AUTOSAR XML (schema 4-2-2)
package /STELLANTIS/EPT/ASWCs
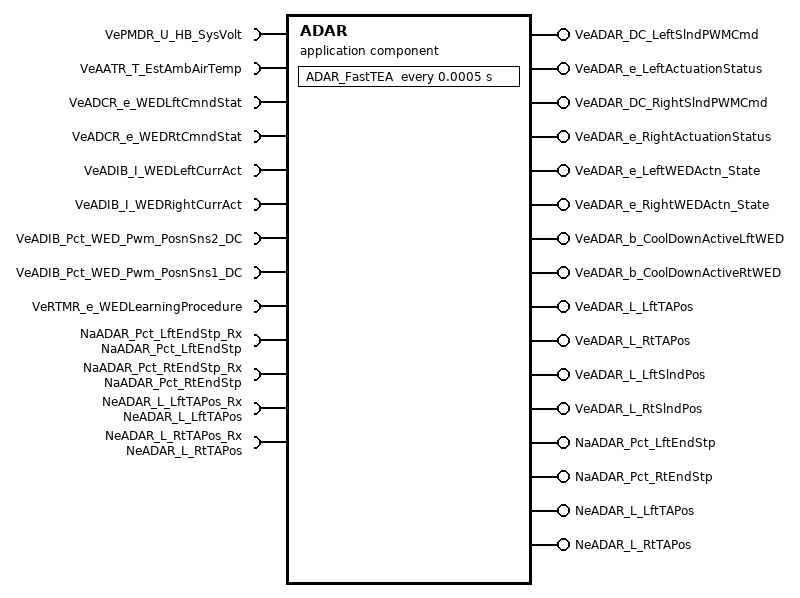
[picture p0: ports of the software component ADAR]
  application sw component type ADAR
    9 x require port:
      VePMDR_U_HB_SysVolt: variation-point={short-label=vpVePMDR_U_HB_SysVolt, sw-syscond=1}, nonqueued-receiver-com-spec{data-element=Value, init-value=0}, required-interface=VePMDR_U_HB_SysVolt
      VeAATR_T_EstAmbAirTemp: variation-point={short-label=vpVeAATR_T_EstAmbAirTemp, sw-syscond=1}, nonqueued-receiver-com-spec{data-element=Value, init-value=0}, required-interface=VeAATR_T_EstAmbAirTemp
      VeADCR_e_WEDLftCmndStat: variation-point={short-label=vpVeADCR_e_WEDLftCmndStat, sw-syscond=1}, nonqueued-receiver-com-spec{data-element=Value, init-value=CeADCR_e_NoCmnd}, required-interface=VeADCR_e_WEDLftCmndStat
      VeADCR_e_WEDRtCmndStat: variation-point={short-label=vpVeADCR_e_WEDRtCmndStat, sw-syscond=1}, nonqueued-receiver-com-spec{data-element=Value, init-value=CeADCR_e_NoCmnd}, required-interface=VeADCR_e_WEDRtCmndStat
      VeADIB_I_WEDLeftCurrAct: variation-point={short-label=vpVeADIB_I_WEDLeftCurrAct, sw-syscond=1}, nonqueued-receiver-com-spec{data-element=Value, init-value=0}, required-interface=VeADIB_I_WEDLeftCurrAct
      VeADIB_I_WEDRightCurrAct: variation-point={short-label=vpVeADIB_I_WEDRightCurrAct, sw-syscond=1}, nonqueued-receiver-com-spec{data-element=Value, init-value=0}, required-interface=VeADIB_I_WEDRightCurrAct
      VeADIB_Pct_WED_Pwm_PosnSns2_DC: variation-point={short-label=vpVeADIB_Pct_WED_Pwm_PosnSns2_DC, sw-syscond=1}, nonqueued-receiver-com-spec{data-element=Value, init-value=0}, required-interface=VeADIB_Pct_WED_Pwm_PosnSns2_DC
      VeADIB_Pct_WED_Pwm_PosnSns1_DC: variation-point={short-label=vpVeADIB_Pct_WED_Pwm_PosnSns1_DC, sw-syscond=1}, nonqueued-receiver-com-spec{data-element=Value, init-value=0}, required-interface=VeADIB_Pct_WED_Pwm_PosnSns1_DC
      VeRTMR_e_WEDLearningProcedure: variation-point={short-label=vpVeRTMR_e_WEDLearningProcedure, sw-syscond=1}, nonqueued-receiver-com-spec{data-element=Value, init-value=CeRTMR_e_WED_Not_Active}, required-interface=VeRTMR_e_WEDLearningProcedure
    12 x provide port:
      VeADAR_DC_LeftSlndPWMCmd: nonqueued-sender-com-spec{data-element=Value, init-value=0}, provided-interface=VeADAR_DC_LeftSlndPWMCmd
      VeADAR_e_LeftActuationStatus: nonqueued-sender-com-spec{data-element=Value, init-value=CeADAR_e_SS_Indeterminate}, provided-interface=VeADAR_e_LeftActuationStatus
      VeADAR_DC_RightSlndPWMCmd: nonqueued-sender-com-spec{data-element=Value, init-value=0}, provided-interface=VeADAR_DC_RightSlndPWMCmd
      VeADAR_e_RightActuationStatus: nonqueued-sender-com-spec{data-element=Value, init-value=CeADAR_e_SS_Indeterminate}, provided-interface=VeADAR_e_RightActuationStatus
      VeADAR_e_LeftWEDActn_State: nonqueued-sender-com-spec{data-element=Value, init-value=CeADAR_e_Indeterminate}, provided-interface=VeADAR_e_LeftWEDActn_State
      VeADAR_e_RightWEDActn_State: nonqueued-sender-com-spec{data-element=Value, init-value=CeADAR_e_Indeterminate}, provided-interface=VeADAR_e_RightWEDActn_State
      VeADAR_b_CoolDownActiveLftWED: nonqueued-sender-com-spec{data-element=Value, init-value=0}, provided-interface=VeADAR_b_CoolDownActiveLftWED
      VeADAR_b_CoolDownActiveRtWED: nonqueued-sender-com-spec{data-element=Value, init-value=0}, provided-interface=VeADAR_b_CoolDownActiveRtWED
      VeADAR_L_LftTAPos: nonqueued-sender-com-spec{data-element=Value, init-value=0}, provided-interface=VeADAR_L_LftTAPos
      VeADAR_L_RtTAPos: nonqueued-sender-com-spec{data-element=Value, init-value=0}, provided-interface=VeADAR_L_RtTAPos
      VeADAR_L_LftSlndPos: nonqueued-sender-com-spec{data-element=Value, init-value=0}, provided-interface=VeADAR_L_LftSlndPos
      VeADAR_L_RtSlndPos: nonqueued-sender-com-spec{data-element=Value, init-value=0}, provided-interface=VeADAR_L_RtSlndPos
    4 x require port:
      NaADAR_Pct_LftEndStp_Rx: nv-require-com-spec{init-value=[0, 0, 0, 0], variable=NaADAR_Pct_LftEndStp}, required-interface=NaADAR_Pct_LftEndStp
      NaADAR_Pct_RtEndStp_Rx: nv-require-com-spec{init-value=[0, 0, 0, 0], variable=NaADAR_Pct_RtEndStp}, required-interface=NaADAR_Pct_RtEndStp
      NeADAR_L_LftTAPos_Rx: nv-require-com-spec{init-value=0, variable=NeADAR_L_LftTAPos}, required-interface=NeADAR_L_LftTAPos
      NeADAR_L_RtTAPos_Rx: nv-require-com-spec{init-value=0, variable=NeADAR_L_RtTAPos}, required-interface=NeADAR_L_RtTAPos
    4 x provide port:
      NaADAR_Pct_LftEndStp: nv-provide-com-spec{ram-block-init-value=[0, 0, 0, 0], variable=NaADAR_Pct_LftEndStp}, provided-interface=NaADAR_Pct_LftEndStp
      NaADAR_Pct_RtEndStp: nv-provide-com-spec{ram-block-init-value=[0, 0, 0, 0], variable=NaADAR_Pct_RtEndStp}, provided-interface=NaADAR_Pct_RtEndStp
      NeADAR_L_LftTAPos: nv-provide-com-spec{ram-block-init-value=0, variable=NeADAR_L_LftTAPos}, provided-interface=NeADAR_L_LftTAPos
      NeADAR_L_RtTAPos: nv-provide-com-spec{ram-block-init-value=0, variable=NeADAR_L_RtTAPos}, provided-interface=NeADAR_L_RtTAPos
    behavior IB_ADAR: data-type-mapping=msADTtoIDTMapping, handle-termination-and-restart=NO-SUPPORT, included-data-type-set=data-type=[TeADAR_e_ActuationStages, TeADAR_e_CurrntProtectionStatus]
      timing event Event_FastTEA: start-on-event=ADAR_FastTEA, period=0.0005
      init event Event_ADAR_ac_Init: start-on-event=ADAR_ac_Init
      init event Event_PwrOn: start-on-event=ADAR_PwrOn
      init event Event_PwrOff: start-on-event=ADAR_PwrOff
      4 x runnable:
        ADAR_ac_Init
          data-send-points:
            4 x access:
              OUT_VeADAR_e_LeftActuationStatus_Value: accessed-variable=VeADAR_e_LeftActuationStatus.Value
              OUT_VeADAR_e_RightActuationStatus_Value: accessed-variable=VeADAR_e_RightActuationStatus.Value
              OUT_VeADAR_e_LeftWEDActn_State_Value: accessed-variable=VeADAR_e_LeftWEDActn_State.Value
              OUT_VeADAR_e_RightWEDActn_State_Value: accessed-variable=VeADAR_e_RightWEDActn_State.Value
        ADAR_PwrOn
          data-receive-point-by-arguments:
            4 x access:
              IN_NaADAR_Pct_LftEndStp_Rx_NaADAR_Pct_LftEndStp: accessed-variable=NaADAR_Pct_LftEndStp_Rx.NaADAR_Pct_LftEndStp
              IN_NaADAR_Pct_RtEndStp_Rx_NaADAR_Pct_RtEndStp: accessed-variable=NaADAR_Pct_RtEndStp_Rx.NaADAR_Pct_RtEndStp
              IN_NeADAR_L_LftTAPos_Rx_NeADAR_L_LftTAPos: accessed-variable=NeADAR_L_LftTAPos_Rx.NeADAR_L_LftTAPos
              IN_NeADAR_L_RtTAPos_Rx_NeADAR_L_RtTAPos: accessed-variable=NeADAR_L_RtTAPos_Rx.NeADAR_L_RtTAPos
          data-send-points:
            12 x access:
              OUT_VeADAR_e_LeftActuationStatus_Value: accessed-variable=VeADAR_e_LeftActuationStatus.Value
              OUT_VeADAR_DC_LeftSlndPWMCmd_Value: accessed-variable=VeADAR_DC_LeftSlndPWMCmd.Value
              OUT_VeADAR_e_RightActuationStatus_Value: accessed-variable=VeADAR_e_RightActuationStatus.Value
              OUT_VeADAR_DC_RightSlndPWMCmd_Value: accessed-variable=VeADAR_DC_RightSlndPWMCmd.Value
              OUT_VeADAR_e_LeftWEDActn_State_Value: accessed-variable=VeADAR_e_LeftWEDActn_State.Value
              OUT_VeADAR_e_RightWEDActn_State_Value: accessed-variable=VeADAR_e_RightWEDActn_State.Value
              OUT_VeADAR_b_CoolDownActiveLftWED_Value: accessed-variable=VeADAR_b_CoolDownActiveLftWED.Value
              OUT_VeADAR_b_CoolDownActiveRtWED_Value: accessed-variable=VeADAR_b_CoolDownActiveRtWED.Value
              OUT_VeADAR_L_LftTAPos_Value: accessed-variable=VeADAR_L_LftTAPos.Value
              OUT_VeADAR_L_RtTAPos_Value: accessed-variable=VeADAR_L_RtTAPos.Value
              OUT_VeADAR_L_LftSlndPos_Value: accessed-variable=VeADAR_L_LftSlndPos.Value
              OUT_VeADAR_L_RtSlndPos_Value: accessed-variable=VeADAR_L_RtSlndPos.Value
        ADAR_FastTEA
          data-receive-point-by-arguments:
            9 x access:
              IN_VeAATR_T_EstAmbAirTemp_Value: accessed-variable=VeAATR_T_EstAmbAirTemp.Value, variation-point={short-label=vpIN_VeAATR_T_EstAmbAirTemp_Value, sw-syscond=1}
              IN_VeADCR_e_WEDLftCmndStat_Value: accessed-variable=VeADCR_e_WEDLftCmndStat.Value, variation-point={short-label=vpIN_VeADCR_e_WEDLftCmndStat_Value, sw-syscond=1}
              IN_VeADCR_e_WEDRtCmndStat_Value: accessed-variable=VeADCR_e_WEDRtCmndStat.Value, variation-point={short-label=vpIN_VeADCR_e_WEDRtCmndStat_Value, sw-syscond=1}
              IN_VeADIB_I_WEDLeftCurrAct_Value: accessed-variable=VeADIB_I_WEDLeftCurrAct.Value, variation-point={short-label=vpIN_VeADIB_I_WEDLeftCurrAct_Value, sw-syscond=1}
              IN_VeADIB_I_WEDRightCurrAct_Value: accessed-variable=VeADIB_I_WEDRightCurrAct.Value, variation-point={short-label=vpIN_VeADIB_I_WEDRightCurrAct_Value, sw-syscond=1}
              IN_VeADIB_Pct_WED_Pwm_PosnSns1_DC_Value: accessed-variable=VeADIB_Pct_WED_Pwm_PosnSns1_DC.Value, variation-point={short-label=vpIN_VeADIB_Pct_WED_Pwm_PosnSns1_DC_Value, sw-syscond=1}
              IN_VeADIB_Pct_WED_Pwm_PosnSns2_DC_Value: accessed-variable=VeADIB_Pct_WED_Pwm_PosnSns2_DC.Value, variation-point={short-label=vpIN_VeADIB_Pct_WED_Pwm_PosnSns2_DC_Value, sw-syscond=1}
              IN_VePMDR_U_HB_SysVolt_Value: accessed-variable=VePMDR_U_HB_SysVolt.Value, variation-point={short-label=vpIN_VePMDR_U_HB_SysVolt_Value, sw-syscond=1}
              IN_VeRTMR_e_WEDLearningProcedure_Value: accessed-variable=VeRTMR_e_WEDLearningProcedure.Value, variation-point={short-label=vpIN_VeRTMR_e_WEDLearningProcedure_Value, sw-syscond=1}
          data-send-points:
            12 x access:
              OUT_VeADAR_e_LeftActuationStatus_Value: accessed-variable=VeADAR_e_LeftActuationStatus.Value
              OUT_VeADAR_DC_LeftSlndPWMCmd_Value: accessed-variable=VeADAR_DC_LeftSlndPWMCmd.Value
              OUT_VeADAR_e_LeftWEDActn_State_Value: accessed-variable=VeADAR_e_LeftWEDActn_State.Value
              OUT_VeADAR_e_RightActuationStatus_Value: accessed-variable=VeADAR_e_RightActuationStatus.Value
              OUT_VeADAR_DC_RightSlndPWMCmd_Value: accessed-variable=VeADAR_DC_RightSlndPWMCmd.Value
              OUT_VeADAR_e_RightWEDActn_State_Value: accessed-variable=VeADAR_e_RightWEDActn_State.Value
              OUT_VeADAR_b_CoolDownActiveLftWED_Value: accessed-variable=VeADAR_b_CoolDownActiveLftWED.Value
              OUT_VeADAR_b_CoolDownActiveRtWED_Value: accessed-variable=VeADAR_b_CoolDownActiveRtWED.Value
              OUT_VeADAR_L_LftTAPos_Value: accessed-variable=VeADAR_L_LftTAPos.Value
              OUT_VeADAR_L_RtTAPos_Value: accessed-variable=VeADAR_L_RtTAPos.Value
              OUT_VeADAR_L_LftSlndPos_Value: accessed-variable=VeADAR_L_LftSlndPos.Value
              OUT_VeADAR_L_RtSlndPos_Value: accessed-variable=VeADAR_L_RtSlndPos.Value
        ADAR_PwrOff
          data-send-points:
            4 x access:
              OUT_NaADAR_Pct_LftEndStp_NaADAR_Pct_LftEndStp: accessed-variable=NaADAR_Pct_LftEndStp.NaADAR_Pct_LftEndStp
              OUT_NaADAR_Pct_RtEndStp_NaADAR_Pct_RtEndStp: accessed-variable=NaADAR_Pct_RtEndStp.NaADAR_Pct_RtEndStp
              OUT_NeADAR_L_LftTAPos_NeADAR_L_LftTAPos: accessed-variable=NeADAR_L_LftTAPos.NeADAR_L_LftTAPos
              OUT_NeADAR_L_RtTAPos_NeADAR_L_RtTAPos: accessed-variable=NeADAR_L_RtTAPos.NeADAR_L_RtTAPos
      variation point proxy Variant_ADAR_EnblLftWEDActnCtrl: category=CONDITION, condition-access=1
      variation point proxy Variant_ADAR_EnblRtWEDActnCtrl: category=CONDITION, condition-access=1
